# ESP32-S31 register map
Vendor: ESPRESSIF SYSTEMS (SHANGHAI) CO., LTD.; Series: ESP32 S-Series; File version: 1
CPU: RV32IMAFC r0p0, little endian, no MPU, FPU, 0 interrupt priority bits
Address unit: 32 bits
Registers are 32-bit, read-write, reset 0x0 unless marked. A register's access mark holds for its fields unless they carry their own. Offsets are from the block's base; [hi:lo] are bit positions; {n}, {i} and the like mark numbered series; <NAME> marks a mode.

## HMAC — HMAC (Hash-based Message Authentication Code) Accelerator
Base 0x2050D000
0x40 SET_START wo — HMAC start control register
  [0] SET_START — Configures whether or not to enable HMAC. \\0: Disable HMAC \\1: Enable HMAC
0x44 SET_PARA_PURPOSE wo — HMAC parameter configuration register
  [3:0] PURPOSE_SET — Configures the HMAC purpose, refer to the Table <a href=tab:hmac-key-purpose">link</a>. "
0x48 SET_PARA_KEY wo — HMAC parameters configuration register
  [2:0] KEY_SET — Configures HMAC key. There are six keys with index 0~5. Write the index of the selected key to this field.
0x4C SET_PARA_FINISH wo — HMAC configuration completion register
  [0] SET_PARA_END — Configures whether to finish HMAC configuration. \\0: No effect \\1: Finish configuration
0x50 SET_MESSAGE_ONE wo — HMAC message control register
  [0] SET_TEXT_ONE — Calls SHA to calculate one message block.
0x54 SET_MESSAGE_ING wo — HMAC message continue register
  [0] SET_TEXT_ING — Configures whether or not there are unprocessed message blocks. \\0: No unprocessed message block \\1: There are still some message blocks to be processed.
0x58 SET_MESSAGE_END wo — HMAC message end register
  [0] SET_TEXT_END — Configures whether to start hardware padding. \\0: No effect \\1: Start hardware padding
0x5C SET_RESULT_FINISH wo — HMAC result reading finish register
  [0] SET_RESULT_END — Configures whether to exit upstream mode and clear calculation results. \\0: Not exit \\1: Exit upstream mode and clear calculation results.
0x60 SET_INVALIDATE_JTAG wo — Invalidate JTAG result register
  [0] SET_INVALIDATE_JTAG — Configures whether or not to clear calculation results when re-enabling JTAG in downstream mode. \\0: Not clear \\1: Clear calculation results
0x64 SET_INVALIDATE_DS wo — Invalidate digital signature result register
  [0] SET_INVALIDATE_DS — Configures whether or not to clear calculation results of the DS module in downstream mode. \\0: Not clear \\1: Clear calculation results
0x68 QUERY_ERROR ro — Stores matching results between keys generated by users and corresponding purposes
  [0] QUREY_CHECK — Represents whether or not an HMAC key matches the purpose. \\0: Match \\1: Error
0x6C QUERY_BUSY ro — Busy state of HMAC module
  [0] BUSY_STATE — Represents whether or not HMAC is in a busy state. Before configuring HMAC, please make sure HMAC is in an IDLE state. \\0: Idle \\1: HMAC is still working on the calculation
0x70 TIMEOUT_LIMIT reset 0xFFFFFFFF — HMAC timeout limit configurate register
  [31:0] TIMEOUT_LIMIT — The timeout limitation for waiting sub-IP.
{0x80+i} WR_MESSAGE_MEM[{i}] (i=0..63) 8-bit access not given — Message block memory.
{0xC0+i} RD_RESULT_MEM[{i}] (i=0..31) 8-bit access not given — Result from upstream.
0xF0 SET_MESSAGE_PAD wo — Software padding register
  [0] SET_TEXT_PAD — Configures whether or not the padding is applied by software. \\0: Not applied by software \\1: Applied by software
0xF4 ONE_BLOCK wo — One block message register
  [0] SET_ONE_BLOCK — Write 1 to indicate there is only one block which already contains padding bits and there is no need for padding.
0xF8 SOFT_JTAG_CTRL wo — Jtag register 0.
  [0] SOFT_JTAG_CTRL — Configures whether or not to enable JTAG authentication mode. \\0: Disable \\1: Enable \\
0xFC WR_JTAG wo — Re-enable JTAG register 1
  [31:0] WR_JTAG — Writes the comparing input used for re-enabling JTAG.
0x1FC DATE reset 0x20250819 — Version control register
  [29:0] DATE — Hmac date information/ hmac version information.

## LP_HUK — LP_HUK Peripheral
Base 0x20703000
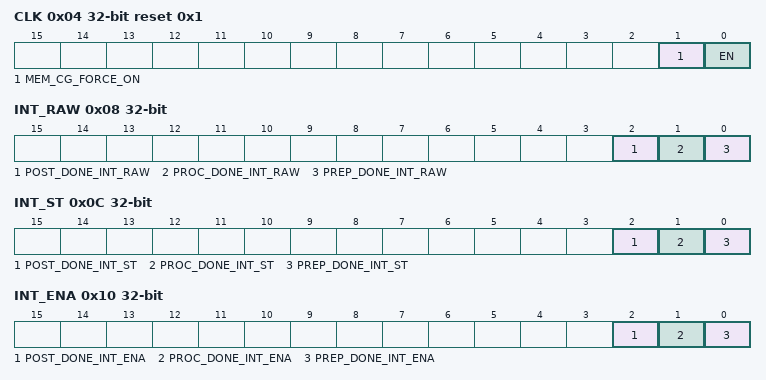
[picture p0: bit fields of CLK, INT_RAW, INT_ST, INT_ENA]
0x04 CLK reset 0x1 — HUK Generator clock gate control register
  [1] MEM_CG_FORCE_ON — Write 1 to force on memory clock gate.
  [0] EN — Write 1 to force on register clock gate.
0x08 INT_RAW ro — HUK Generator interrupt raw register, valid in level.
  [2] POST_DONE_INT_RAW — The raw interrupt status bit for the huk_post_done_int interrupt
  [1] PROC_DONE_INT_RAW — The raw interrupt status bit for the huk_proc_done_int interrupt
  [0] PREP_DONE_INT_RAW — The raw interrupt status bit for the huk_prep_done_int interrupt
0x0C INT_ST ro — HUK Generator interrupt status register.
  [2] POST_DONE_INT_ST — The masked interrupt status bit for the huk_post_done_int interrupt
  [1] PROC_DONE_INT_ST — The masked interrupt status bit for the huk_proc_done_int interrupt
  [0] PREP_DONE_INT_ST — The masked interrupt status bit for the huk_prep_done_int interrupt
0x10 INT_ENA — HUK Generator interrupt enable register.
  [2] POST_DONE_INT_ENA — The interrupt enable bit for the huk_post_done_int interrupt
  [1] PROC_DONE_INT_ENA — The interrupt enable bit for the huk_proc_done_int interrupt
  [0] PREP_DONE_INT_ENA — The interrupt enable bit for the huk_prep_done_int interrupt
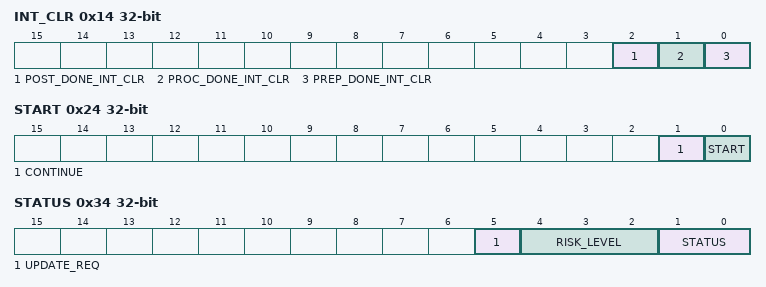
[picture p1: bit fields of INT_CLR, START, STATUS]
0x14 INT_CLR wo — HUK Generator interrupt clear register.
  [2] POST_DONE_INT_CLR — Set this bit to clear the huk_post_done_int interrupt
  [1] PROC_DONE_INT_CLR — Set this bit to clear the huk_proc_done_int interrupt
  [0] PREP_DONE_INT_CLR — Set this bit to clear the huk_prep_done_int interrupt
0x20 CONF — HUK Generator configuration register
  [0] MODE — Set this field to choose the huk process. 1: process huk generate mode. 0: process huk recovery mode.
0x24 START wo — HUK Generator control register
  [1] CONTINUE — Write 1 to start HUK Generator at IDLE state.
  [0] START — Write 1 to continue HUK Generator operation at LOAD/GAIN state.
0x28 STATE ro — HUK Generator state register
  [1:0] STATE — The state of HUK Generator. 0: IDLE. 1: LOAD. 2: GAIN. 3: BUSY.
0x34 STATUS ro — HUK Generator HUK status register
  [5] UPDATE_REQ — The update request of HUK info. 0: User can update HUK info according to the risk level. 1: The HUK info is expired, and user need to update it.
  [4:2] RISK_LEVEL — The risk level of HUK. 0-6: the higher the risk level is, the more error bits there are in the PUF SRAM. 7: Error Level, HUK is invalid.
  [1:0] STATUS — The HUK generation status. 0: HUK is not generated. 1: HUK is generated and valid. 2: HUK is generated but invalid. 3: reserved.
0xFC DATE reset 0x2404070 — Version control register
  [27:0] DATE — HUK Generator version control register.
{0x100+i} INFO_MEM[{i}] (i=0..383) 8-bit access not given — The memory that stores HUK info.
